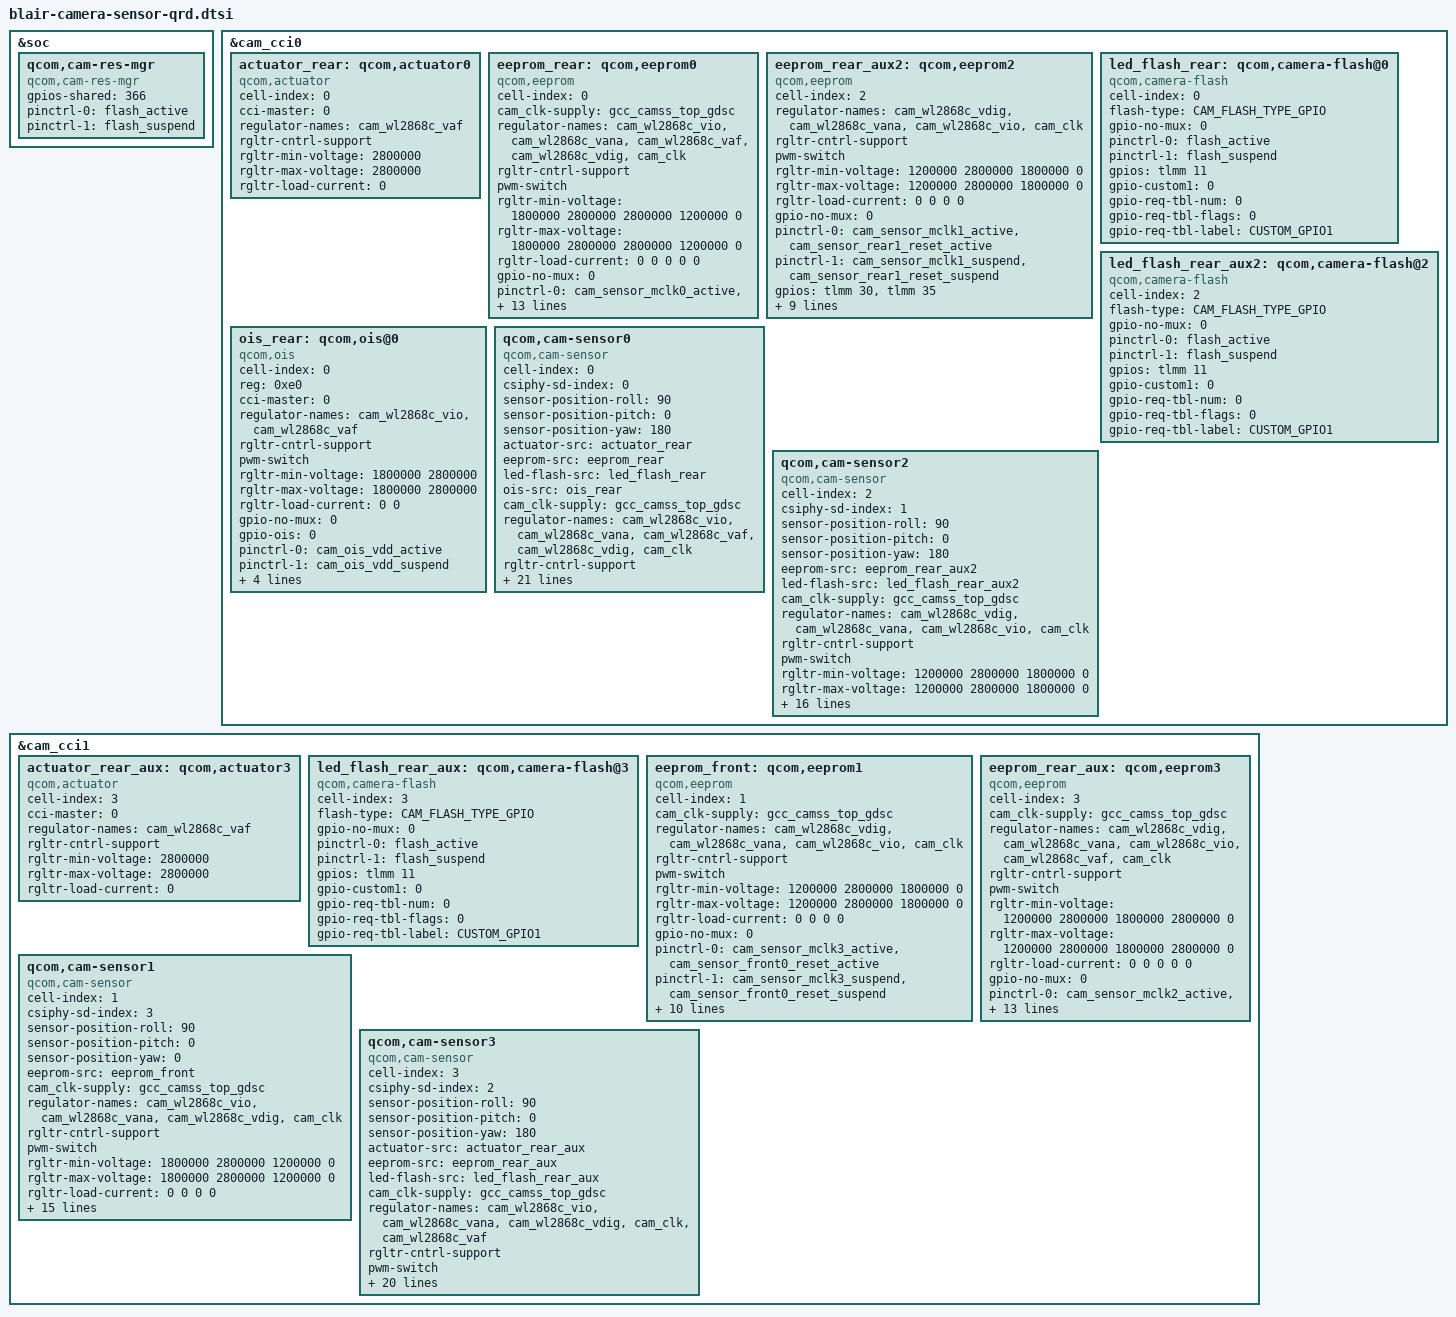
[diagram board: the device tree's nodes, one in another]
#include <dt-bindings/clock/qcom,gcc-blair.h>
#include <dt-bindings/msm/msm-camera.h>
#include "blair-camera-flash-pwm.dtsi"

&soc {
	qcom,cam-res-mgr {
		compatible = "qcom,cam-res-mgr";
		status = "ok";
        gpios-shared = <366>;
        pinctrl-names = "flash_active", "flash_suspend";
		pinctrl-0 = <&flash_active>;
		pinctrl-1 = <&flash_suspend>;
	};
};

&cam_cci0 {
	actuator_rear: qcom,actuator0 {
		cell-index = <0>;
		compatible = "qcom,actuator";
		cci-master = <0>;
		//cam_vaf-supply = <&L5P>;
		regulator-names = "cam_wl2868c_vaf";
		rgltr-cntrl-support;
		rgltr-min-voltage = <2800000>;
		rgltr-max-voltage = <2800000>;
		rgltr-load-current = <0>;
		status = "ok";
	};

	eeprom_rear: qcom,eeprom0 {
		cell-index = <0>;
		compatible = "qcom,eeprom";
		//cam_vio-supply = <&L6P>;
		//cam_vana-supply = <&L4P>;
		//cam_vdig-supply = <&L2P>;
		cam_clk-supply = <&gcc_camss_top_gdsc>;
		//cam_vaf-supply = <&L5P>;
		regulator-names = "cam_wl2868c_vio", "cam_wl2868c_vana", "cam_wl2868c_vaf", "cam_wl2868c_vdig", "cam_clk";
		rgltr-cntrl-support;
		pwm-switch;
		rgltr-min-voltage = <1800000 2800000 2800000 1200000 0>;
		rgltr-max-voltage = <1800000 2800000 2800000 1200000 0>;
		rgltr-load-current = <0 0 0 0 0>;
		gpio-no-mux = <0>;
		pinctrl-names = "cam_default", "cam_suspend";
		pinctrl-0 = <&cam_sensor_mclk0_active
				&cam_sensor_rear0_reset_active>;
		pinctrl-1 = <&cam_sensor_mclk0_suspend
				&cam_sensor_rear0_reset_suspend>;
		gpios = <&tlmm 29 0>,
			<&tlmm 34 0>;
		gpio-reset = <1>;
		gpio-req-tbl-num = <0 1>;
		gpio-req-tbl-flags = <1 0>;
		gpio-req-tbl-label = "CAMIF_MCLK0",
					"CAM_RESET0";
		sensor-mode = <0>;
		cci-master = <0>;
		status = "ok";
		clocks = <&gcc GCC_CAMSS_MCLK0_CLK>;
		clock-names = "cam_clk";
		clock-cntl-level = "turbo";
		clock-rates = <19200000>;
	};

	eeprom_rear_aux2: qcom,eeprom2 {
		cell-index = <2>;
		compatible = "qcom,eeprom";
		//cam_vio-supply = <&L6P>;
		//cam_vana-supply = <&L3P>;
		//cam_vdig-supply = <&L1P>;
		regulator-names = "cam_wl2868c_vdig", "cam_wl2868c_vana", "cam_wl2868c_vio", "cam_clk";
		rgltr-cntrl-support;
		pwm-switch;
		rgltr-min-voltage = <1200000 2800000 1800000 0>;
		rgltr-max-voltage = <1200000 2800000 1800000 0>;
		rgltr-load-current = <0 0 0 0>;
		gpio-no-mux = <0>;
		pinctrl-names = "cam_default", "cam_suspend";
		pinctrl-0 = <&cam_sensor_mclk1_active
				&cam_sensor_rear1_reset_active>;
		pinctrl-1 = <&cam_sensor_mclk1_suspend
				&cam_sensor_rear1_reset_suspend>;
		gpios = <&tlmm 30 0>,
			<&tlmm 35 0>;
		gpio-reset = <1>;
		gpio-req-tbl-num = <0 1>;
		gpio-req-tbl-flags = <1 0>;
		gpio-req-tbl-label = "CAMIF_MCLK1",
					"CAM_RESET1";
		sensor-mode = <0>;
		cci-master = <1>;
		status = "ok";
		clocks = <&gcc GCC_CAMSS_MCLK1_CLK>;
		clock-names = "cam_clk";
		clock-cntl-level = "turbo";
		clock-rates = <19200000>;
	};

	led_flash_rear: qcom,camera-flash@0 {
		cell-index = <0>;
		compatible = "qcom,camera-flash";
		flash-type = <CAM_FLASH_TYPE_GPIO>;
		gpio-no-mux = <0>;
		pinctrl-names = "cam_default", "cam_suspend";
		pinctrl-0 = <&flash_active>;
		pinctrl-1 = <&flash_suspend>;
		gpios = <&tlmm 11 0>;
        gpio-custom1 = <0>;
		gpio-req-tbl-num = <0>;
		gpio-req-tbl-flags = <0>;
		gpio-req-tbl-label = "CUSTOM_GPIO1";
		status = "ok";
	};

	led_flash_rear_aux2: qcom,camera-flash@2 {
		cell-index = <2>;
		compatible = "qcom,camera-flash";
		flash-type = <CAM_FLASH_TYPE_GPIO>;
		gpio-no-mux = <0>;
		pinctrl-names = "cam_default", "cam_suspend";
		pinctrl-0 = <&flash_active>;
		pinctrl-1 = <&flash_suspend>;
		gpios = <&tlmm 11 0>;
        gpio-custom1 = <0>;
		gpio-req-tbl-num = <0>;
		gpio-req-tbl-flags = <0>;
		gpio-req-tbl-label = "CUSTOM_GPIO1";
		status = "ok";
	};

        ois_rear: qcom,ois@0 {
            cell-index = <0>;
            reg = <0xe0>;
            compatible = "qcom,ois";
            cci-master = <0>;
            //cam_vaf-supply = <&actuator_rear>;
            regulator-names = "cam_wl2868c_vio","cam_wl2868c_vaf";
            rgltr-cntrl-support;
            pwm-switch;
            rgltr-min-voltage = <1800000 2800000>;
            rgltr-max-voltage = <1800000 2800000>;
            rgltr-load-current = <0 0>;
            gpio-no-mux = <0>;
            gpio-ois = <0>;
            pinctrl-names = "cam_default", "cam_suspend";
            pinctrl-0 = <&cam_ois_vdd_active>;
            pinctrl-1 = <&cam_ois_vdd_suspend>;
            gpios = <&tlmm 33 0>;
            gpio-req-tbl-num = <0>;
            gpio-req-tbl-flags = <0>;
            gpio-req-tbl-label = "OIS_VDD";
            status = "ok";
        };

	/* Rear*/
	qcom,cam-sensor0 {
		cell-index = <0>;
		compatible = "qcom,cam-sensor";
		csiphy-sd-index = <0>;
		sensor-position-roll = <90>;
		sensor-position-pitch = <0>;
		sensor-position-yaw = <180>;
		actuator-src = <&actuator_rear>;
		eeprom-src = <&eeprom_rear>;
		led-flash-src = <&led_flash_rear>;
		ois-src = <&ois_rear>;
		//cam_vio-supply = <&L6P>;
		//cam_vana-supply = <&L4P>;
		//cam_vaf-supply = <&L5P>;
		//cam_vdig-supply = <&L2P>;
		cam_clk-supply = <&gcc_camss_top_gdsc>;
		regulator-names = "cam_wl2868c_vio", "cam_wl2868c_vana", "cam_wl2868c_vaf", "cam_wl2868c_vdig", "cam_clk";
		rgltr-cntrl-support;
		pwm-switch;
		rgltr-min-voltage = <1800000 2800000 2800000 1200000 0>;
		rgltr-max-voltage = <1800000 2800000 2800000 1200000 0>;
		rgltr-load-current = <0 0 0 0 0>;
		gpio-no-mux = <0>;
		pinctrl-names = "cam_default", "cam_suspend";
		pinctrl-0 = <&cam_sensor_mclk0_active
				&cam_sensor_rear0_reset_active>;
		pinctrl-1 = <&cam_sensor_mclk0_suspend
				&cam_sensor_rear0_reset_suspend>;
		gpios = <&tlmm 29 0>,
			<&tlmm 34 0>;
		gpio-reset = <1>;
		gpio-req-tbl-num = <0 1>;
		gpio-req-tbl-flags = <1 0>;
		gpio-req-tbl-label = "CAMIF_MCLK0",
					"CAM_RESET0";
		sensor-mode = <0>;
		cci-master = <0>;
		status = "ok";
		clocks = <&gcc GCC_CAMSS_MCLK0_CLK>;
		clock-names = "cam_clk";
		clock-cntl-level = "turbo";
		clock-rates = <19200000>;
	};

	/*Rear Aux2*/
	qcom,cam-sensor2 {
		cell-index = <2>;
		compatible = "qcom,cam-sensor";
		csiphy-sd-index = <1>;
		sensor-position-roll = <90>;
		sensor-position-pitch = <0>;
		sensor-position-yaw = <180>;
		eeprom-src = <&eeprom_rear_aux2>;
		led-flash-src = <&led_flash_rear_aux2>;
		//cam_vio-supply = <&L6P>;
		//cam_vana-supply = <&L3P>;
		//cam_vdig-supply = <&L1P>;
		cam_clk-supply = <&gcc_camss_top_gdsc>;
		regulator-names = "cam_wl2868c_vdig", "cam_wl2868c_vana", "cam_wl2868c_vio", "cam_clk";
		rgltr-cntrl-support;
		pwm-switch;
		rgltr-min-voltage = <1200000 2800000 1800000 0>;
		rgltr-max-voltage = <1200000 2800000 1800000 0>;
		rgltr-load-current = <0 0 0 0>;
		gpio-no-mux = <0>;
		pinctrl-names = "cam_default", "cam_suspend";
		pinctrl-0 = <&cam_sensor_mclk1_active
				&cam_sensor_rear1_reset_active>;
		pinctrl-1 = <&cam_sensor_mclk1_suspend
				&cam_sensor_rear1_reset_suspend>;
		gpios = <&tlmm 30 0>,
			<&tlmm 35 0>;
		gpio-reset = <1>;
		gpio-req-tbl-num = <0 1>;
		gpio-req-tbl-flags = <1 0>;
		gpio-req-tbl-label = "CAMIF_MCLK1",
					"CAM_RESET1";
		sensor-mode = <0>;
		cci-master = <1>;
		status = "ok";
		clocks = <&gcc GCC_CAMSS_MCLK1_CLK>;
		clock-names = "cam_clk";
		clock-cntl-level = "turbo";
		clock-rates = <19200000>;
	};

};

&cam_cci1 {
	actuator_rear_aux: qcom,actuator3 {
		cell-index = <3>;
		compatible = "qcom,actuator";
		cci-master= <0>;
		//cam_vaf-supply = <&L5P>;
		regulator-names = "cam_wl2868c_vaf";
		rgltr-cntrl-support;
		rgltr-min-voltage = <2800000>;
		rgltr-max-voltage = <2800000>;
		rgltr-load-current = <0>;
		status = "ok";
	};

	led_flash_rear_aux: qcom,camera-flash@3 {
		cell-index = <3>;
		compatible = "qcom,camera-flash";
		flash-type = <CAM_FLASH_TYPE_GPIO>;
		gpio-no-mux = <0>;
		pinctrl-names = "cam_default", "cam_suspend";
		pinctrl-0 = <&flash_active>;
		pinctrl-1 = <&flash_suspend>;
		gpios = <&tlmm 11 0>;
		gpio-custom1 = <0>;
		gpio-req-tbl-num = <0>;
		gpio-req-tbl-flags = <0>;
		gpio-req-tbl-label = "CUSTOM_GPIO1";
		status = "ok";
	};

	eeprom_front: qcom,eeprom1 {
		cell-index = <1>;
		compatible = "qcom,eeprom";
		//cam_vio-supply = <&L6P>;
		//cam_vana-supply = <&L3P>;
		//cam_vdig-supply = <&L2P>;
		cam_clk-supply = <&gcc_camss_top_gdsc>;
		regulator-names = "cam_wl2868c_vdig", "cam_wl2868c_vana", "cam_wl2868c_vio", "cam_clk";
		rgltr-cntrl-support;
		pwm-switch;
		rgltr-min-voltage = <1200000 2800000 1800000 0>;
		rgltr-max-voltage = <1200000 2800000 1800000 0>;
		rgltr-load-current = <0 0 0 0>;
		gpio-no-mux = <0>;
		pinctrl-names = "cam_default", "cam_suspend";
		pinctrl-0 = <&cam_sensor_mclk3_active
		             &cam_sensor_front0_reset_active>;
		pinctrl-1 = <&cam_sensor_mclk3_suspend
		             &cam_sensor_front0_reset_suspend>;
		gpios = <&tlmm 32 0>,
		        <&tlmm 37 0>;
		gpio-reset = <1>;
		gpio-req-tbl-num = <0 1>;
		gpio-req-tbl-flags = <1 0>;
		gpio-req-tbl-label = "CAMIF_MCLK3",
		                     "CAM_RESET3";
		sensor-mode = <1>;
		cci-master = <1>;
		status = "ok";
		clocks = <&gcc GCC_CAMSS_MCLK3_CLK>;
		clock-names = "cam_clk";
		clock-cntl-level = "turbo";
		clock-rates = <19200000>;
	};

	eeprom_rear_aux: qcom,eeprom3 {
		cell-index = <3>;
		compatible = "qcom,eeprom";
		//cam_vio-supply = <&L6P>;
		//cam_vana-supply = <&L7P>;
		//cam_vdig-supply = <&L1P>;
		cam_clk-supply = <&gcc_camss_top_gdsc>;
		//cam_vaf-supply = <&L5P>;
		regulator-names = "cam_wl2868c_vdig", "cam_wl2868c_vana", "cam_wl2868c_vio",  "cam_wl2868c_vaf", "cam_clk";
		rgltr-cntrl-support;
		pwm-switch;
		rgltr-min-voltage = <1200000 2800000 1800000 2800000 0>;
		rgltr-max-voltage = <1200000 2800000 1800000 2800000 0>;
		rgltr-load-current = <0 0 0 0 0>;
		gpio-no-mux = <0>;
		pinctrl-names = "cam_default", "cam_suspend";
		pinctrl-0 = <&cam_sensor_mclk2_active
				&cam_sensor_rear2_reset_active>;
		pinctrl-1 = <&cam_sensor_mclk2_suspend
				&cam_sensor_rear2_reset_suspend>;
		gpios = <&tlmm 31 0>,
			<&tlmm 36 0>;
		gpio-reset = <1>;
		gpio-req-tbl-num = <0 1>;
		gpio-req-tbl-flags = <1 0>;
		gpio-req-tbl-label = "CAMIF_MCLK2",
					"CAM_RESET2";
		sensor-mode = <1>;
		cci-master = <0>;
		status = "ok";
		clocks = <&gcc GCC_CAMSS_MCLK2_CLK>;
		clock-names = "cam_clk";
		clock-cntl-level = "turbo";
		clock-rates = <19200000>;
	};

	/*Front*/
	qcom,cam-sensor1 {
		cell-index = <1>;
		compatible = "qcom,cam-sensor";
		csiphy-sd-index = <3>;
		sensor-position-roll = <90>;
		sensor-position-pitch = <0>;
		sensor-position-yaw = <0>;
		eeprom-src = <&eeprom_front>;
		//cam_vio-supply = <&L6P>;
		//cam_vana-supply = <&L3P>;
		//cam_vdig-supply = <&L2P>;
		cam_clk-supply = <&gcc_camss_top_gdsc>;
		regulator-names = "cam_wl2868c_vio", "cam_wl2868c_vana", "cam_wl2868c_vdig",
			"cam_clk";
		rgltr-cntrl-support;
		pwm-switch;
		rgltr-min-voltage = <1800000 2800000 1200000 0>;
		rgltr-max-voltage = <1800000 2800000 1200000 0>;
		rgltr-load-current = <0 0 0 0>;
		gpio-no-mux = <0>;
		pinctrl-names = "cam_default", "cam_suspend";
		pinctrl-0 = <&cam_sensor_mclk3_active
				&cam_sensor_front0_reset_active>;
		pinctrl-1 = <&cam_sensor_mclk3_suspend
				&cam_sensor_front0_reset_suspend>;
		gpios = <&tlmm 32 0>,
			<&tlmm 37 0>;
		gpio-reset = <1>;
		gpio-req-tbl-num = <0 1>;
		gpio-req-tbl-flags = <1 0>;
		gpio-req-tbl-label = "CAMIF_MCLK3",
					"CAM_RESET3";
		sensor-mode = <1>;
		cci-master = <1>;
		status = "ok";
		clocks = <&gcc GCC_CAMSS_MCLK3_CLK>;
		clock-names = "cam_clk";
		clock-cntl-level = "turbo";
		clock-rates = <19200000>;
	};

	/*Rear Aux*/
	qcom,cam-sensor3 {
		cell-index = <3>;
		compatible = "qcom,cam-sensor";
		csiphy-sd-index = <2>;
		sensor-position-roll = <90>;
		sensor-position-pitch = <0>;
		sensor-position-yaw = <180>;
		actuator-src = <&actuator_rear_aux>;
		eeprom-src = <&eeprom_rear_aux>;
		led-flash-src = <&led_flash_rear_aux>;
		//cam_vio-supply = <&L6P>;
		//cam_vana-supply = <&L7P>;
		//cam_vdig-supply = <&L1P>;
		cam_clk-supply = <&gcc_camss_top_gdsc>;
		//cam_vaf-supply = <&L5P>;
		regulator-names = "cam_wl2868c_vio", "cam_wl2868c_vana", "cam_wl2868c_vdig",
			"cam_clk", "cam_wl2868c_vaf";
		rgltr-cntrl-support;
		pwm-switch;
		rgltr-min-voltage = <1800000 2800000 1200000 0 2800000>;
		rgltr-max-voltage = <1800000 2800000 1200000 0 2800000>;
		rgltr-load-current = <0 0 0 0 0>;
		gpio-no-mux = <0>;
		pinctrl-names = "cam_default", "cam_suspend";
		pinctrl-0 = <&cam_sensor_mclk2_active
				&cam_sensor_rear2_reset_active>;
		pinctrl-1 = <&cam_sensor_mclk2_suspend
				&cam_sensor_rear2_reset_suspend>;
		gpios = <&tlmm 31 0>,
			<&tlmm 36 0>;
		gpio-reset = <1>;
		gpio-req-tbl-num = <0 1>;
		gpio-req-tbl-flags = <1 0>;
		gpio-req-tbl-label = "CAMIF_MCLK2",
					"CAM_RESET2";
		sensor-mode = <0>;
		cci-master = <0>;
		status = "ok";
		clocks = <&gcc GCC_CAMSS_MCLK2_CLK>;
		clock-names = "cam_clk";
		clock-cntl-level = "turbo";
		clock-rates = <19200000>;
	};
};
